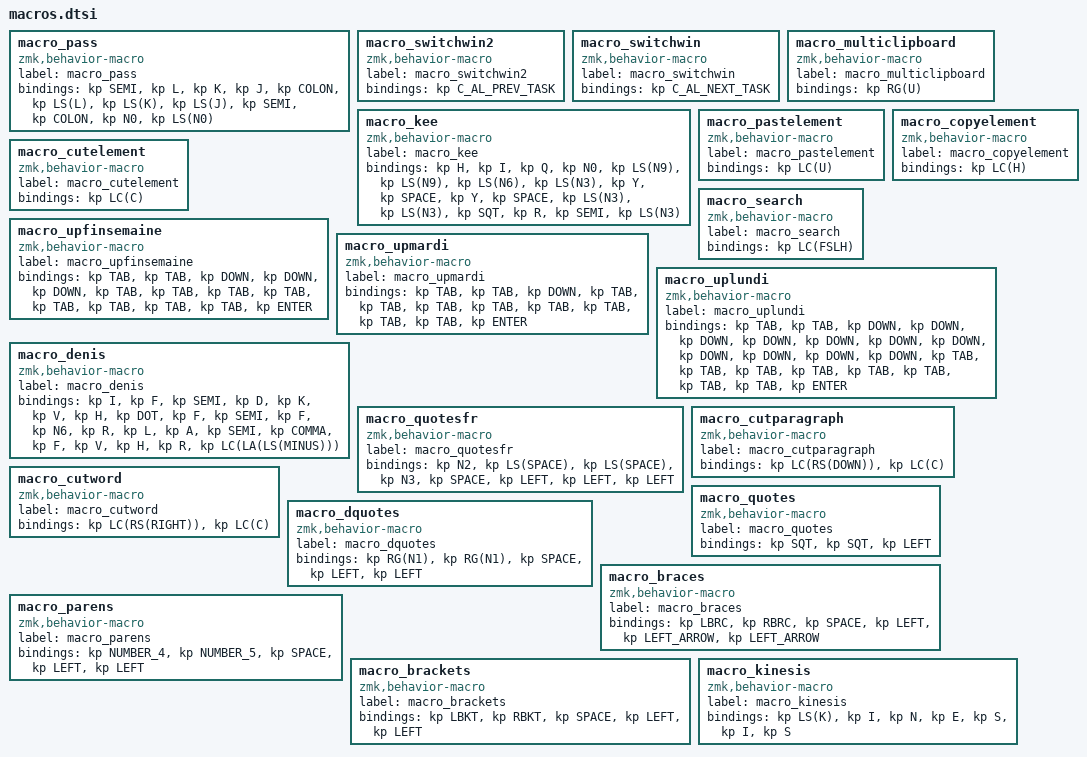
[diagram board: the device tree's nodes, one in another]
macro_pass: macro_pass{
compatible = "zmk,behavior-macro";
label = "macro_pass";
#binding-cells = <0>;
bindings = <&kp SEMI>, <&kp L>, <&kp K>, <&kp J>, <&kp COLON>, <&kp LS(L)>, <&kp LS(K)>, <&kp LS(J)>, <&kp SEMI>, <&kp COLON>, <&kp N0>, <&kp LS(N0)>;
};
macro_switchwin2: macro_switchwin2{
compatible = "zmk,behavior-macro";
label = "macro_switchwin2";
#binding-cells = <0>;
bindings = <&kp C_AL_PREV_TASK>;
};
macro_switchwin: macro_switchwin{
compatible = "zmk,behavior-macro";
label = "macro_switchwin";
#binding-cells = <0>;
bindings = <&kp C_AL_NEXT_TASK>;
};
macro_kee: macro_kee{
compatible = "zmk,behavior-macro";
label = "macro_kee";
#binding-cells = <0>;
bindings = <&kp H>, <&kp I>, <&kp Q>, <&kp N0>, <&kp LS(N9)>, <&kp LS(N9)>, <&kp LS(N6)>, <&kp LS(N3)>, <&kp Y>, <&kp SPACE>, <&kp Y>, <&kp SPACE>, <&kp LS(N3)>, <&kp LS(N3)>, <&kp SQT>, <&kp R>, <&kp SEMI>, <&kp LS(N3)>;
};
macro_multiclipboard: macro_multiclipboard{
compatible = "zmk,behavior-macro";
label = "macro_multiclipboard";
#binding-cells = <0>;
bindings = <&kp RG(U)>;
};
macro_pastelement: macro_pastelement{
compatible = "zmk,behavior-macro";
label = "macro_pastelement";
#binding-cells = <0>;
bindings = <&kp LC(U)>;
};
macro_copyelement: macro_copyelement{
compatible = "zmk,behavior-macro";
label = "macro_copyelement";
#binding-cells = <0>;
bindings = <&kp LC(H)>;
};
macro_cutelement: macro_cutelement{
compatible = "zmk,behavior-macro";
label = "macro_cutelement";
#binding-cells = <0>;
bindings = <&kp LC(C)>;
};
macro_search: macro_search{
compatible = "zmk,behavior-macro";
label = "macro_search";
#binding-cells = <0>;
bindings = <&kp LC(FSLH)>;
};
macro_upfinsemaine: macro_upfinsemaine{
compatible = "zmk,behavior-macro";
label = "macro_upfinsemaine";
#binding-cells = <0>;
bindings = <&kp TAB>, <&kp TAB>, <&kp DOWN>, <&kp DOWN>, <&kp DOWN>, <&kp TAB>, <&kp TAB>, <&kp TAB>, <&kp TAB>, <&kp TAB>, <&kp TAB>, <&kp TAB>, <&kp TAB>, <&kp ENTER>;
};
macro_upmardi: macro_upmardi{
compatible = "zmk,behavior-macro";
label = "macro_upmardi";
#binding-cells = <0>;
bindings = <&kp TAB>, <&kp TAB>, <&kp DOWN>, <&kp TAB>, <&kp TAB>, <&kp TAB>, <&kp TAB>, <&kp TAB>, <&kp TAB>, <&kp TAB>, <&kp TAB>, <&kp ENTER>;
};
macro_uplundi: macro_uplundi{
compatible = "zmk,behavior-macro";
label = "macro_uplundi";
#binding-cells = <0>;
bindings = <&kp TAB>, <&kp TAB>, <&kp DOWN>, <&kp DOWN>, <&kp DOWN>, <&kp DOWN>, <&kp DOWN>, <&kp DOWN>, <&kp DOWN>, <&kp DOWN>, <&kp DOWN>, <&kp DOWN>, <&kp DOWN>, <&kp TAB>, <&kp TAB>, <&kp TAB>, <&kp TAB>, <&kp TAB>, <&kp TAB>, <&kp TAB>, <&kp TAB>, <&kp ENTER>;
};
macro_denis: macro_denis{
compatible = "zmk,behavior-macro";
label = "macro_denis";
#binding-cells = <0>;
bindings = <&kp I>, <&kp F>, <&kp SEMI>, <&kp D>, <&kp K>, <&kp V>, <&kp H>, <&kp DOT>, <&kp F>, <&kp SEMI>, <&kp F>, <&kp N6>, <&kp R>, <&kp L>, <&kp A>, <&kp SEMI>, <&kp COMMA>, <&kp F>, <&kp V>, <&kp H>, <&kp R>, <&kp LC(LA(LS(MINUS)))>;
};
macro_quotesfr: macro_quotesfr{
compatible = "zmk,behavior-macro";
label = "macro_quotesfr";
#binding-cells = <0>;
bindings = <&kp N2>, <&kp LS(SPACE)>, <&kp LS(SPACE)>, <&kp N3>, <&kp SPACE>, <&kp LEFT>, <&kp LEFT>, <&kp LEFT>;
};
macro_cutparagraph: macro_cutparagraph{
compatible = "zmk,behavior-macro";
label = "macro_cutparagraph";
#binding-cells = <0>;
bindings = <&kp LC(RS(DOWN))>, <&kp LC(C)>;
};
macro_cutword: macro_cutword{
compatible = "zmk,behavior-macro";
label = "macro_cutword";
#binding-cells = <0>;
bindings = <&kp LC(RS(RIGHT))>, <&kp LC(C)>;
};
macro_quotes: macro_quotes{
compatible = "zmk,behavior-macro";
label = "macro_quotes";
#binding-cells = <0>;
bindings = <&kp SQT>, <&kp SQT>, <&kp LEFT>;
};
macro_dquotes: macro_dquotes{
compatible = "zmk,behavior-macro";
label = "macro_dquotes";
#binding-cells = <0>;
bindings = <&kp RG(N1)>, <&kp RG(N1)>, <&kp SPACE>, <&kp LEFT>, <&kp LEFT>;
};
macro_braces: macro_braces{
compatible = "zmk,behavior-macro";
label = "macro_braces";
#binding-cells = <0>;
bindings = <&kp LBRC>, <&kp RBRC>, <&kp SPACE>, <&kp LEFT>, <&kp LEFT_ARROW>, <&kp LEFT_ARROW>;
};
macro_parens: macro_parens{
compatible = "zmk,behavior-macro";
label = "macro_parens";
#binding-cells = <0>;
bindings = <&kp NUMBER_4>, <&kp NUMBER_5>, <&kp SPACE>, <&kp LEFT>, <&kp LEFT>;
};
macro_brackets: macro_brackets{
compatible = "zmk,behavior-macro";
label = "macro_brackets";
#binding-cells = <0>;
bindings = <&kp LBKT>, <&kp RBKT>, <&kp SPACE>, <&kp LEFT>, <&kp LEFT>;
};
macro_kinesis: macro_kinesis{
compatible = "zmk,behavior-macro";
label = "macro_kinesis";
#binding-cells = <0>;
bindings = <&kp LS(K)>, <&kp I>, <&kp N>, <&kp E>, <&kp S>, <&kp I>, <&kp S>;
};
